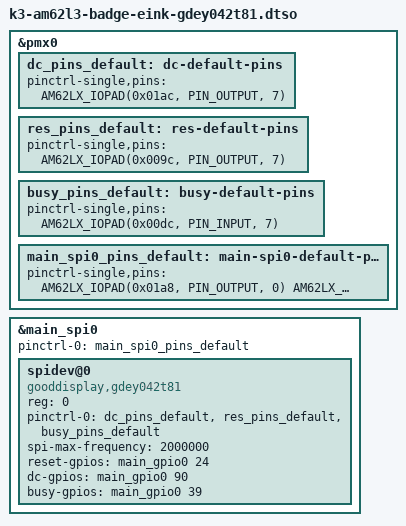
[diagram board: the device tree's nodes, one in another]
// SPDX-License-Identifier: GPL-2.0-or-later OR MIT
/**
 * DT Overlay for GoodDisplay GDEY042T81 E-Ink Display on AM62L Badge
 *
 * Copyright (C) 2025 Texas Instruments Incorporated - https://www.ti.com/
 */

/dts-v1/;
/plugin/;

#include <dt-bindings/gpio/gpio.h>
#include "k3-pinctrl.h"

&pmx0 {

	dc_pins_default: dc-default-pins {
		pinctrl-single,pins = <
			AM62LX_IOPAD(0x01ac, PIN_OUTPUT, 7) /* (E12) SPI0_D0.GPIO0_90 */
		>;
	};

	res_pins_default: res-default-pins {
		pinctrl-single,pins = <
			AM62LX_IOPAD(0x009c, PIN_OUTPUT, 7) /* (H20) GPMC0_AD9.GPIO0_24 */
		>;
	};

	busy_pins_default: busy-default-pins {
		pinctrl-single,pins = <
			AM62LX_IOPAD(0x00dc, PIN_INPUT, 7) /* (N21) GPMC0_WPn.GPIO0_39 */
		>;
	};

	main_spi0_pins_default: main-spi0-default-pins {
		pinctrl-single,pins = <
			AM62LX_IOPAD(0x01a8, PIN_OUTPUT, 0) /* (E13) SPI0_CLK */
			AM62LX_IOPAD(0x01a0, PIN_OUTPUT, 0) /* (E11) SPI0_CS0 */
			AM62LX_IOPAD(0x01b0, PIN_OUTPUT, 0) /* (B12) SPI0_D1 */
		>;
	};

};

&main_spi0 {
	pinctrl-names = "default";
	pinctrl-0 = <&main_spi0_pins_default>;
	status = "okay";
	#address-cells = <1>;
	#size-cells = <0>;

	spidev@0 {
		compatible = "gooddisplay,gdey042t81";
		reg = <0>;
		pinctrl-names = "default";
		pinctrl-0 = <&dc_pins_default>,
			    <&res_pins_default>,
			    <&busy_pins_default>;
		spi-max-frequency = <2000000>;
		reset-gpios = <&main_gpio0 24 GPIO_ACTIVE_HIGH>;
		dc-gpios = <&main_gpio0 90 GPIO_ACTIVE_HIGH>;
		busy-gpios = <&main_gpio0 39 GPIO_ACTIVE_HIGH>;
	};
};
